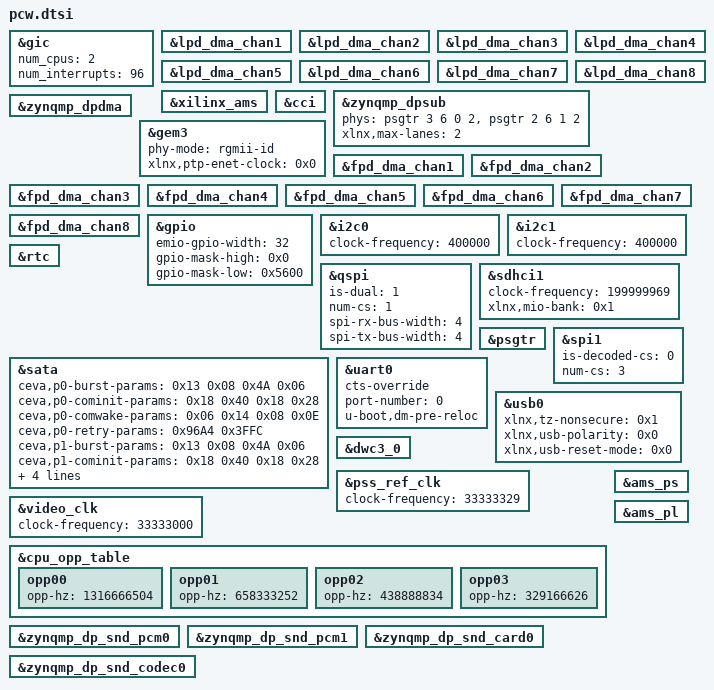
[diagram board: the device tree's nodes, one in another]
/*
 * CAUTION: This file is automatically generated by Xilinx.
 * Version: XSCT 2021.1
 * Today is: Fri Mar 15 14:25:38 2024
 */


&gic {
	num_cpus = <2>;
	num_interrupts = <96>;
};
&lpd_dma_chan1 {
	status = "okay";
};
&lpd_dma_chan2 {
	status = "okay";
};
&lpd_dma_chan3 {
	status = "okay";
};
&lpd_dma_chan4 {
	status = "okay";
};
&lpd_dma_chan5 {
	status = "okay";
};
&lpd_dma_chan6 {
	status = "okay";
};
&lpd_dma_chan7 {
	status = "okay";
};
&lpd_dma_chan8 {
	status = "okay";
};
&xilinx_ams {
	status = "okay";
};
&cci {
	status = "okay";
};
&zynqmp_dpsub {
	phy-names = "dp-phy0","dp-phy1";
	phys = <&psgtr 3 6 0 2>, <&psgtr 2 6 1 2>;
	status = "okay";
	xlnx,max-lanes = <2>;
};
&zynqmp_dpdma {
	status = "okay";
};
&gem3 {
	phy-mode = "rgmii-id";
	status = "okay";
	xlnx,ptp-enet-clock = <0x0>;
};
&fpd_dma_chan1 {
	status = "okay";
};
&fpd_dma_chan2 {
	status = "okay";
};
&fpd_dma_chan3 {
	status = "okay";
};
&fpd_dma_chan4 {
	status = "okay";
};
&fpd_dma_chan5 {
	status = "okay";
};
&fpd_dma_chan6 {
	status = "okay";
};
&fpd_dma_chan7 {
	status = "okay";
};
&fpd_dma_chan8 {
	status = "okay";
};
&gpio {
	emio-gpio-width = <32>;
	gpio-mask-high = <0x0>;
	gpio-mask-low = <0x5600>;
	status = "okay";
};
&i2c0 {
	clock-frequency = <400000>;
	status = "okay";
};
&i2c1 {
	clock-frequency = <400000>;
	status = "okay";
};
&qspi {
	is-dual = <1>;
	num-cs = <1>;
	spi-rx-bus-width = <4>;
	spi-tx-bus-width = <4>;
	status = "okay";
};
&rtc {
	status = "okay";
};
&sata {
	ceva,p0-burst-params = /bits/ 8 <0x13 0x08 0x4A 0x06>;
	ceva,p0-cominit-params = /bits/ 8 <0x18 0x40 0x18 0x28>;
	ceva,p0-comwake-params = /bits/ 8 <0x06 0x14 0x08 0x0E>;
	ceva,p0-retry-params = /bits/ 16 <0x96A4 0x3FFC>;
	ceva,p1-burst-params = /bits/ 8 <0x13 0x08 0x4A 0x06>;
	ceva,p1-cominit-params = /bits/ 8 <0x18 0x40 0x18 0x28>;
	ceva,p1-comwake-params = /bits/ 8 <0x06 0x14 0x08 0x0E>;
	ceva,p1-retry-params = /bits/ 16 <0x96A4 0x3FFC>;
	status = "okay";
	xlnx,tz-nonsecure-sata0 = <0x0>;
	xlnx,tz-nonsecure-sata1 = <0x0>;
};
&sdhci1 {
	clock-frequency = <199999969>;
	status = "okay";
	xlnx,mio-bank = <0x1>;
};
&psgtr {
	status = "okay";
};
&spi1 {
	is-decoded-cs = <0>;
	num-cs = <3>;
	status = "okay";
};
&uart0 {
	cts-override ;
	device_type = "serial";
	port-number = <0>;
	status = "okay";
	u-boot,dm-pre-reloc ;
};
&usb0 {
	status = "okay";
	xlnx,tz-nonsecure = <0x1>;
	xlnx,usb-polarity = <0x0>;
	xlnx,usb-reset-mode = <0x0>;
};
&dwc3_0 {
	status = "okay";
};
&pss_ref_clk {
	clock-frequency = <33333329>;
};
&video_clk {
	clock-frequency = <33333000>;
};
&cpu_opp_table {
	opp00 {
		opp-hz = /bits/ 64 <1316666504>;
	};
	opp01 {
		opp-hz = /bits/ 64 <658333252>;
	};
	opp02 {
		opp-hz = /bits/ 64 <438888834>;
	};
	opp03 {
		opp-hz = /bits/ 64 <329166626>;
	};
};
&ams_ps {
	status = "okay";
};
&ams_pl {
	status = "okay";
};
&zynqmp_dp_snd_pcm0 {
	status = "okay";
};
&zynqmp_dp_snd_pcm1 {
	status = "okay";
};
&zynqmp_dp_snd_card0 {
	status = "okay";
};
&zynqmp_dp_snd_codec0 {
	status = "okay";
};
